# IPU2_UNICACHE_MMU_AMMU register map
Vendor: Texas Instruments
Peripheral module from a debugger description file (folder am572x).
Registers are 32-bit, access per field, reset 0x0 unless marked. A register's access mark holds for its fields unless they carry their own. Offsets are as the file gives them; lines under a group give offsets from that group; [hi:lo] are bit positions; {n}, {i} and the like mark numbered series; 'fields as' and 'values as' point back to an identical list; <NAME> marks a mode.

## IPU2_UNICACHE_MMU_AMMU
{0x0+4i} CACHE_MMU_LARGE_ADDR_i_{i} (i=0..3) — Large page address
  [31:25] ADDRESS rw — Logical source address
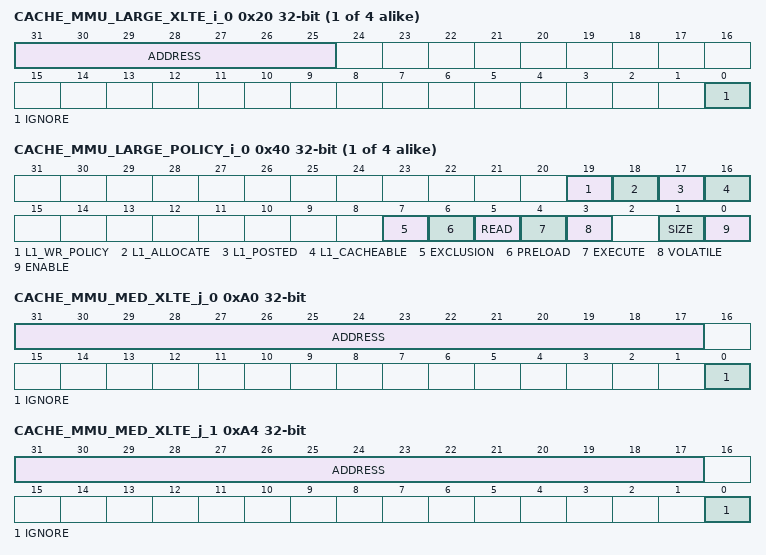
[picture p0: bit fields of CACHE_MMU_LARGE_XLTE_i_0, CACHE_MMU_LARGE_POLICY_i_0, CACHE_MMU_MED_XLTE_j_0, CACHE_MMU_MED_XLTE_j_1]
{0x20+4i} CACHE_MMU_LARGE_XLTE_i_{i} (i=0..3) — Large page translated address
  [31:25] ADDRESS rw — Logical source translated address
  [0] IGNORE rw — Do not use translated address.
{0x40+4i} CACHE_MMU_LARGE_POLICY_i_{i} (i=0..3) — Large page policy
  [19] L1_WR_POLICY rw — L1 write policy
    0=Write_through; 1=Write_back
  [18] L1_ALLOCATE rw — L1 allocate policy
    0=No_writes_are_allocated; 1=Follow_sideband
  [17] L1_POSTED rw — L1 posted policy
    0=Not_posted; 1=Posted
  [16] L1_CACHEABLE rw — L1 cache policy
    0=Non-cacheable; 1=Cacheable
  [7] EXCLUSION rw — Cache exclusion
    0=Do_not_send_exclusion_sideband; 1=Send_exclusion_sideband
  [6] PRELOAD rw — Preload region
    0=Do_not_preload; 1=Preload
  [5] READ rw — Read only
  [4] EXECUTE rw — Execute only
  [3] VOLATILE rw — Volatile qualifier
    0=Do_not_follow_volatile_qualifier; 1=Follow_volatile_qualifier
  [1] SIZE rw — Size of page
    0=32_MiB; 1=512_MiB
  [0] ENABLE rw — Enable page
    0=Page_not_enabled; 1=Page_enabled
0x60 CACHE_MMU_MED_ADDR_j_0 — Medium page address
  [31:17] ADDRESS rw — Logical source address
0x64 CACHE_MMU_MED_ADDR_j_1 — Medium page address
  [31:17] ADDRESS rw — Logical source address
0xA0 CACHE_MMU_MED_XLTE_j_0 — Medium page translated address
  [31:17] ADDRESS rw — Logical source translated address
  [0] IGNORE rw — Do not use translated address.
0xA4 CACHE_MMU_MED_XLTE_j_1 — Medium page translated address
  fields as CACHE_MMU_MED_XLTE_j_0
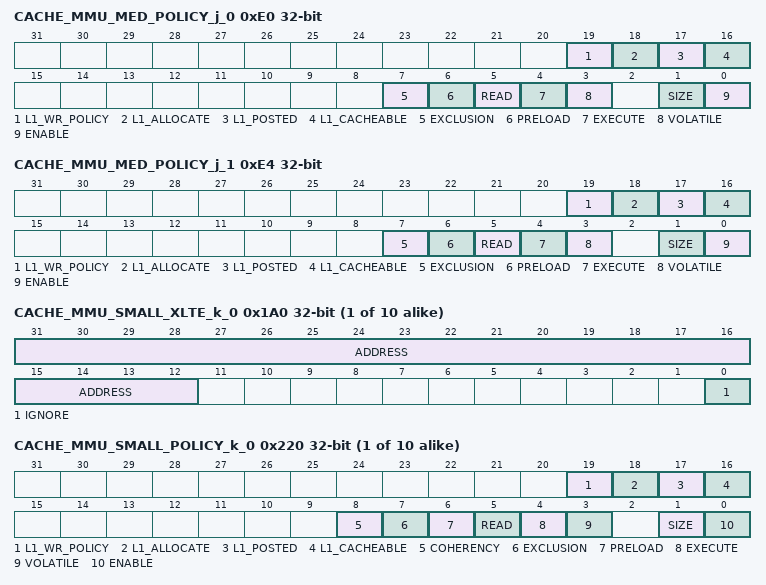
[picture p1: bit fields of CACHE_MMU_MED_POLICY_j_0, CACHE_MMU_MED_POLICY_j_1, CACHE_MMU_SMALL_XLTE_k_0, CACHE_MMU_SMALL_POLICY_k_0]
0xE0 CACHE_MMU_MED_POLICY_j_0 — Medium page policy
  [19] L1_WR_POLICY rw — L1 write policy
    0=Write_through; 1=Write_back
  [18] L1_ALLOCATE rw — L1 allocate policy
    0=No_writes_are_allocated; 1=Follow_sideband
  [17] L1_POSTED rw — L1 posted policy
    0=Non-posted; 1=Posted
  [16] L1_CACHEABLE rw — L1 cache policy
    0=Non-cacheable; 1=Cacheable
  [7] EXCLUSION rw — Cache exclusion
    0=Do_not_send_exclusion_sideband; 1=Send_exclusion_sideband
  [6] PRELOAD rw — Preload region
    0=Do_not_preload; 1=Preload
  [5] READ rw — Read only
  [4] EXECUTE rw — Execute only
  [3] VOLATILE rw — Volatile qualifier
    values as CACHE_MMU_LARGE_POLICY_i_0.VOLATILE
  [1] SIZE rw — Size of page
    0=128_KiB; 1=256_KiB
  [0] ENABLE rw — Enable page
    0=Page_not_enabled; 1=Page_enabled
0xE4 CACHE_MMU_MED_POLICY_j_1 — Medium page policy
  fields as CACHE_MMU_MED_POLICY_j_0
{0x120+4i} CACHE_MMU_SMALL_ADDR_k_{i} (reset mask 0xFFF) (i=0..9) — Small page address
  [31:12] ADDRESS rw — Logical source address
{0x1A0+4i} CACHE_MMU_SMALL_XLTE_k_{i} (reset mask 0xFFF) (i=0..9) — Small page translated address
  [31:12] ADDRESS rw — Logical source translated address
  [0] IGNORE rw — Do not use translated address.
{0x220+4i} CACHE_MMU_SMALL_POLICY_k_{i} (i=0..9) — Small page policy
  [19] L1_WR_POLICY rw — L1 write policy
    0=Write_through; 1=Write_back
  [18] L1_ALLOCATE rw — L1 allocate policy
    0=No_writes_are_allocated; 1=Follow_sideband
  [17] L1_POSTED rw — L1 posted policy
    0=Non-posted; 1=Posted
  [16] L1_CACHEABLE rw — L1 cache policy
    0=Non-cacheable; 1=Cacheable
  [8] COHERENCY ro
  [7] EXCLUSION rw — Cache exclusion
    0=Do_not_send_exclusion_sideband; 1=Send_exclusion_sideband
  [6] PRELOAD rw — Preload region
    0=Do_not_preload; 1=Preload
  [5] READ rw — Read only
  [4] EXECUTE rw — Execute only
  [3] VOLATILE rw — Volatile qualifier
    values as CACHE_MMU_LARGE_POLICY_i_0.VOLATILE
  [1] SIZE rw — Size of page
    0=4_KiB; 1=16_KiB
  [0] ENABLE rw — Enable page
    0=Page_not_enabled; 1=Page_enabled
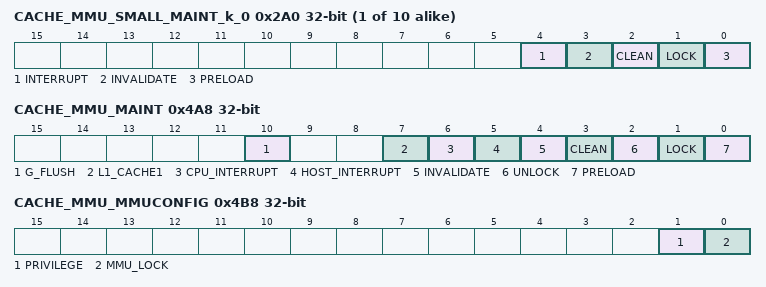
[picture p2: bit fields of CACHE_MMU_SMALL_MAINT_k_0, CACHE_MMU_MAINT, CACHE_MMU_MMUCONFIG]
{0x2A0+4i} CACHE_MMU_SMALL_MAINT_k_{i} (i=0..9) — Small page maintenance configuration
  [4] INTERRUPT rw — Generate interrupt when maintenance operation is complete
  [3] INVALIDATE rw — Invalidate page
  [2] CLEAN rw — Evict page
  [1] LOCK rw — Lock page
  [0] PRELOAD rw — Preload page
0x4A8 CACHE_MMU_MAINT — Maintenance configuration register
  [10] G_FLUSH rw — Global flush bit
    0=Do_nothing,_global_flush_done; 1=Invalidate_L1
  [7] L1_CACHE1 rw — Do maintenance operation in L1 cache
    0=Do_not_perform_maintenance_operation; 1=Perform maintenance operation selected by the maintenance bits
  [6] CPU_INTERRUPT rw — Generate interrupt to cpu when maintenance operation initiated by CPU is complete
    0=Do_not_generate_interrupt; 1=Generate_interrupt
  [5] HOST_INTERRUPT rw — Generate interrupt when maintenance operation is complete
    0=Do_not_generate_interrupt; 1=Generate_interrupt
  [4] INVALIDATE rw — Invalidate lines in region defined by maintenance start/end addresses
    0=Do_nothing; 1=Invalidate
  [3] CLEAN rw — Evict dirty lines in region defined by maintenance start/end addresses
    0=Do_nothing; 1=Clean
  [2] UNLOCK rw — Unlock region defined by maintenance start/end addresses
    0=Do_nothing; 1=Unlock
  [1] LOCK rw — Lock region defined by maintenance start/end addresses
    0=Do_nothing; 1=Lock
  [0] PRELOAD rw — Preload region defined by maintenance start/end addresses
    0=Do_nothing; 1=Preload
0x4AC CACHE_MMU_MTSTART rw — Maintenance start configuration register
  [31:0] BEGIN_ADDRESS — Start address of maintenance operations, resets to 0x0000 0000 when finished
0x4B0 CACHE_MMU_MTEND rw — Maintenance end configuration register
  [31:0] END_ADDRESS — End address of maintenance operations, resets to 0x0000 0000 when finished
0x4B4 CACHE_MMU_MAINTST ro — Maintenance status register
  [0] STATUS — Status bit
    0=Do_nothing,_maintenance_completed; 1=Maintenance_ongoing
0x4B8 CACHE_MMU_MMUCONFIG — MMU configuration register
  [1] PRIVILEGE rw — Privilege bit. Once this bit is set, only global flush, debugger, or hardware reset can clear.
    0=CPU_can_access_everything; 1=CPU_DMA_MMU_1 (CPU can only access maintenance, and DMA cannot access MMU at all.)
  [0] MMU_LOCK rw — MMU lock. Once this bit is set only a global flush, debugger, or hardware reset can clear.
    0=CPU_can_access_everything; 1=CPU_DMA_MMU._1 (CPU can only access maintenance, and DMA cannot access the MMU.)
